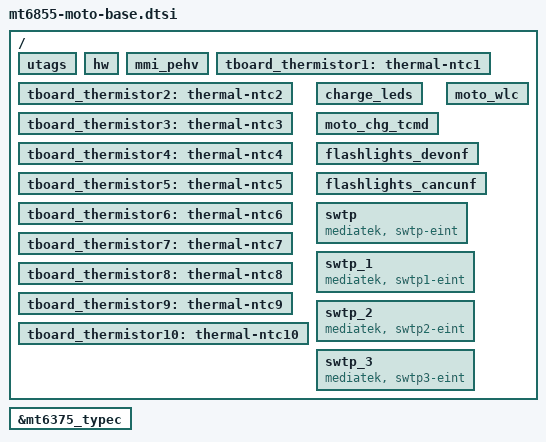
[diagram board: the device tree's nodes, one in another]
/*
 * Things can done here:
 * 	Add nodes or properties to root node
 * 	Delete nodes or properties
*/

/ {
	utags: utags { };
	hw: hw { };
	mmi_pehv: mmi_pehv{};
	tboard_thermistor1: thermal-ntc1 { };
	tboard_thermistor2: thermal-ntc2 { };
	tboard_thermistor3: thermal-ntc3 { };
	tboard_thermistor4: thermal-ntc4 { };
	tboard_thermistor5: thermal-ntc5 { };
	tboard_thermistor6: thermal-ntc6 { };
	tboard_thermistor7: thermal-ntc7 { };
        tboard_thermistor8: thermal-ntc8 { };
        tboard_thermistor9: thermal-ntc9 { };
        tboard_thermistor10: thermal-ntc10 { };
	charge_leds: charge_leds{ };
	moto_chg_tcmd: moto_chg_tcmd { };
	moto_wlc: moto_wlc { };
	flashlights_devonf: flashlights_devonf { };
	flashlights_cancunf: flashlights_cancunf { };
	swtp: swtp {
		compatible = "mediatek, swtp-eint";
	};
	swtp_1: swtp_1 {
		compatible = "mediatek, swtp1-eint";
	};
	swtp_2: swtp_2 {
		compatible = "mediatek, swtp2-eint";
	};
	swtp_3: swtp_3 {
		compatible = "mediatek, swtp3-eint";
	};
};

&mt6375_typec {
	/delete-property/ tcpc,en_wd;
	/delete-property/ tcpc,en_wd_sbu_polling;
	/delete-property/ tcpc,en_wd_polling_only;
};
